# APM32F446 register map
File version: 1.0
CPU: CM4 r0p1, little endian, MPU, FPU, 4 interrupt priority bits
Registers are 32-bit, read-write, reset 0x0 unless marked. A register's access mark holds for its fields unless they carry their own. Offsets are from the block's base; [hi:lo] are bit positions; {n}, {i} and the like mark numbered series; 'fields as' and 'values as' point back to an identical list.

## EWDT — External Watchdog Timer
Base 0x40061000
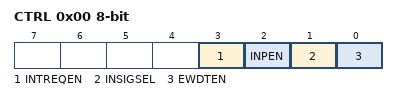
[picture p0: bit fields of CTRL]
0x00 CTRL 8-bit — Control Register
  [3] INTREQEN — Interrupt Request Enable
    0=Disable External Watchdog Timer Interrupt; 1=Enable External Watchdog Timer Interrupt
  [2] INPEN write-once — Input Port Enable
    0=Disable the EWM_in port; 1=Enables the EWM_in port
  [1] INSIGSEL write-once — EWDT_in Signal Assertion State Select
    0=EWDT_in's Assertion State is logic zero; 1=EWDT_in's Assertion State is logic one
  [0] EWDTEN write-once — EWDT Module Enable
    0=Disable External Watchdog Timer; 1=Enable External Watchdog Timer
0x01 SEQ 8-bit wo — Service Register
  [7:0] SEQDATA — Sequence Data Area
0x02 COMPL 8-bit write-once — Compare Low Register
  [7:0] COMPL — Compare Low
0x03 COMPH 8-bit write-once reset 0xFF — Compare High Register
  [7:0] COMPH — Compare High
0x05 CLKPSC 8-bit write-once — Clock Prescaler Register
  [7:0] CLKPSC — Clock Prescaler

## TMC — Trigger MUX Control
Base 0x40063000
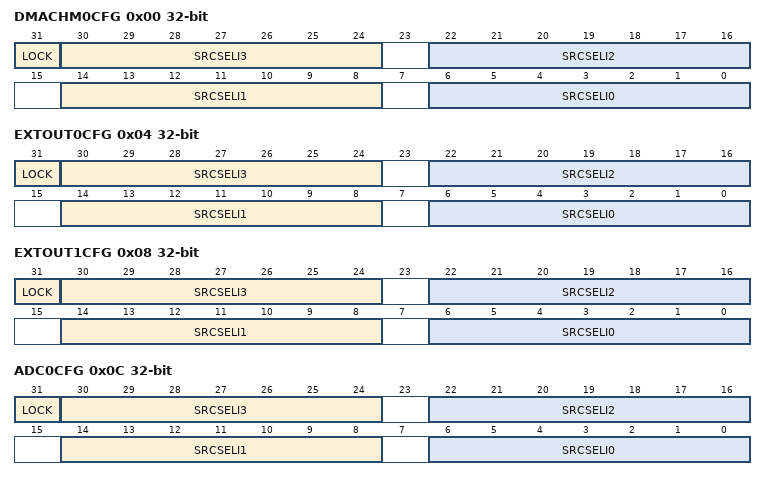
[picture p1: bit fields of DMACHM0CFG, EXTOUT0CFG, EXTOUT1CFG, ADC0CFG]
0x00 DMACHM0CFG — DMACHM0 Configure Register
  [31] LOCK
    0=Register can be written; 1=Register cannot be written until the next system Reset
  [8n+6:8n] SRCSELI{n} (n=0..3) — Input {n} Source Select
0x04 EXTOUT0CFG — EXTOUT0 Configure Register
  fields as DMACHM0CFG
0x08 EXTOUT1CFG — EXTOUT1 Configure Register
  fields as DMACHM0CFG
0x0C ADC0CFG — ADC0 Configure Register
  fields as DMACHM0CFG
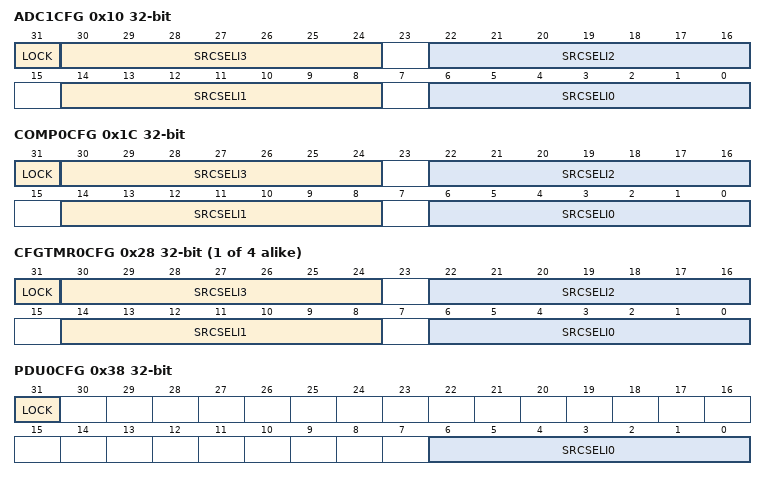
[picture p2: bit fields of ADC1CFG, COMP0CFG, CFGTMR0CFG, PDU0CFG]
0x10 ADC1CFG — ADC1 Configure Register
  fields as DMACHM0CFG
0x1C COMP0CFG — COMP0 Configure Register
  fields as DMACHM0CFG
{0x28+4i} CFGTMR{i}CFG (i=0..3) — CFGTMR{i} Configure Register
  fields as DMACHM0CFG
0x38 PDU0CFG — PDU0 Configure Register
  [31] LOCK
    values as DMACHM0CFG.LOCK
  [6:0] SRCSELI0 — Input 0 Source Select
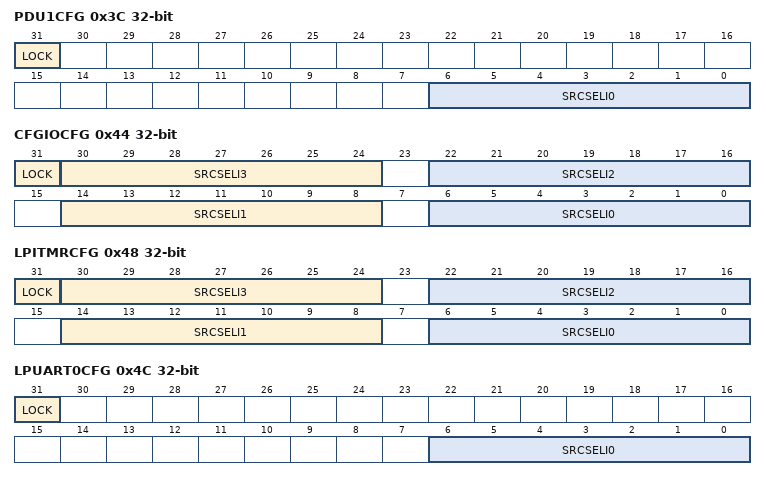
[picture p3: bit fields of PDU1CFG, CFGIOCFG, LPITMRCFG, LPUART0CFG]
0x3C PDU1CFG — PDU1 Configure Register
  fields as PDU0CFG
0x44 CFGIOCFG — CFGIO Configure Register
  fields as DMACHM0CFG
0x48 LPITMRCFG — LPITMR Configure Register
  fields as DMACHM0CFG
0x4C LPUART0CFG — LPUART0 Configure Register
  fields as PDU0CFG
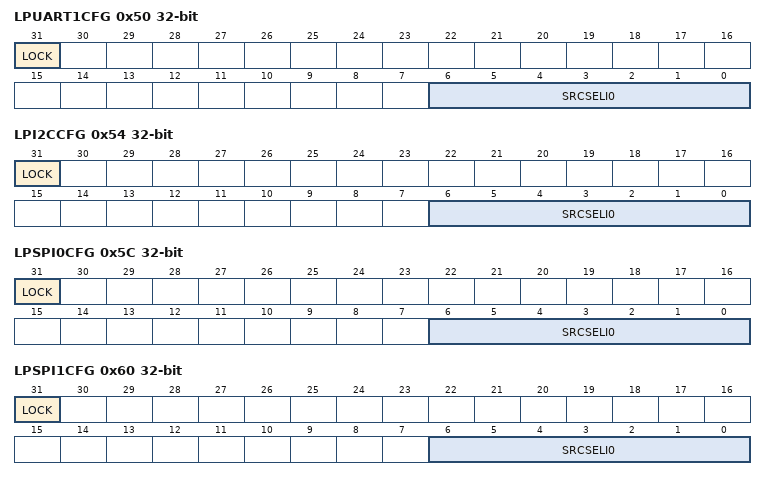
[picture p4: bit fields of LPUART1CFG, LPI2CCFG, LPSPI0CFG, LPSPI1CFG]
0x50 LPUART1CFG — LPUART1 Configure Register
  fields as PDU0CFG
0x54 LPI2CCFG — LPI2C Configure Register
  fields as PDU0CFG
0x5C LPSPI0CFG — LPSPI0 Configure Register
  fields as PDU0CFG
0x60 LPSPI1CFG — LPSPI1 Configure Register
  fields as PDU0CFG
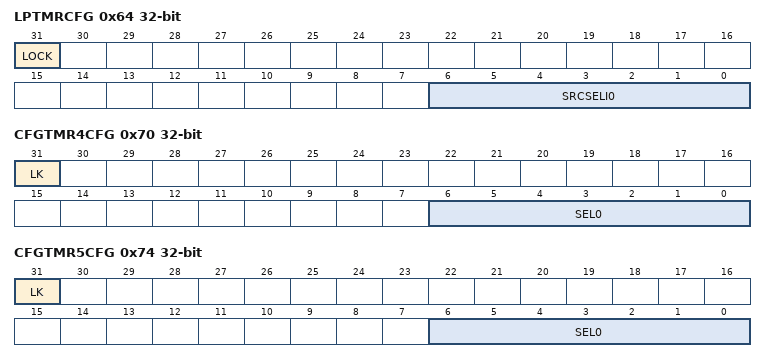
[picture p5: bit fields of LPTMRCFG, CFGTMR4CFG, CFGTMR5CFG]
0x64 LPTMRCFG — LPTMR Configure Register
  fields as PDU0CFG
0x70 CFGTMR4CFG — CFGTMR4 Configure Register
  [31] LK — TRGMUX register lock.
    values as DMACHM0CFG.LOCK
  [6:0] SEL0 — Trigger MUX Input 0 Source Select
0x74 CFGTMR5CFG — CFGTMR5 Configure Register
  fields as CFGTMR4CFG

## PMU — Power management unit
Base 0x4007D000
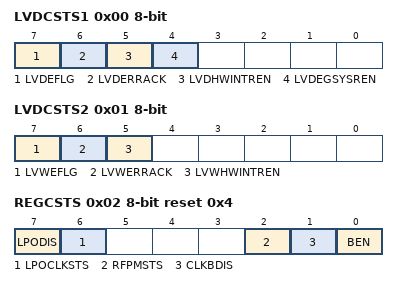
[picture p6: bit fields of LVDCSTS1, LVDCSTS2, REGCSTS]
0x00 LVDCSTS1 8-bit (reset mask 0xEF) — Low Voltage Detect Control and Status1 Register
  [7] LVDEFLG ro — Low-Voltage Warning Event Flag
    0=Low-voltage warning event not detected; 1=Low-voltage warning event detected
  [6] LVDERRACK wo — Low-Voltage Warning Error Acknowledge
  [5] LVDHWINTREN wo — Low-Voltage Warning Error Acknowledge
  [4] LVDEGSYSREN — Low-Voltage Detect Event Generation System Reset Enable
    0=Hardware interrupt disabled (use polling); 1=Request a hardware interrupt when LVWEFLG=1
0x01 LVDCSTS2 8-bit — Low Voltage Detect Control and Status2 Register
  [7] LVWEFLG ro — Low-Voltage Warning Event Flag
    values as LVDCSTS1.LVDEFLG
  [6] LVWERRACK wo — Low-Voltage Warning Error Acknowledge
  [5] LVWHWINTREN — Low-Voltage Warning Hardware Interrupt Enable
    values as LVDCSTS1.LVDEGSYSREN
0x02 REGCSTS 8-bit reset 0x4 (reset mask 0xBF) — Regulator Control and Status Register
  [7] LPODIS — LPO Disable
    0=Low power oscillator enabled; 1=Low power oscillator disabled
  [6] LPOCLKSTS ro — LPO Clock Status
    0=Low power oscillator in low phase; 1=Low power oscillator in high phase
  [2] RFPMSTS ro — Regulator in Full Performance Mode Status
    0=Regulator is in low power mode or transition to/from; 1=Regulator is in full performance mode
  [1] CLKBDIS — Clock Bias Disable
    0=No effect; 1=In VLPS mode, the bias currents and reference voltages for the following clock modules are disabled: LSICLK, HSICLK, PLL. (if available on device)
  [0] BEN — Bias Enable
    0=Biasing disabled, core logic can run in full performance; 1=Biasing enabled, core logic is slower and there are restrictions in allowed system clock speed (see Data Sheet for details)
0x04 LPOSCTRIM 8-bit (reset mask 0xE0) — Low Power Oscillator Trim Register
  [4:0] TLPOF — Trimming Low Power Oscillator Frequency
